VERSION ""

NS_ :

BS_:

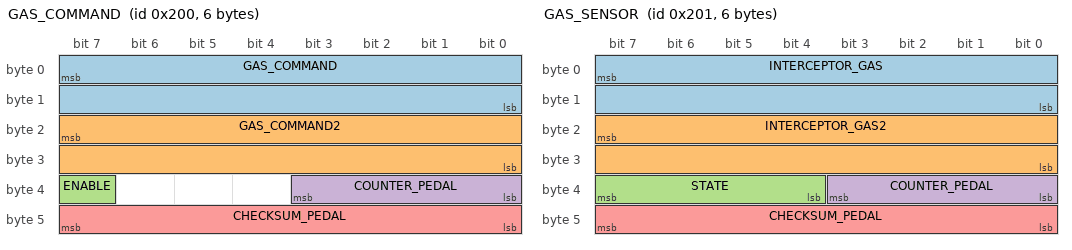
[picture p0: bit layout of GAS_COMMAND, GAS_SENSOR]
BO_ 512 GAS_COMMAND: 6 NEO
 SG_ GAS_COMMAND : 7|16@0+ (0.125677,-75.909) [0|1] "" INTERCEPTOR
 SG_ GAS_COMMAND2 : 23|16@0+ (0.251976,-76.601) [0|1] "" INTERCEPTOR
 SG_ ENABLE : 39|1@0+ (1,0) [0|1] "" INTERCEPTOR
 SG_ COUNTER_PEDAL : 35|4@0+ (1,0) [0|15] "" INTERCEPTOR
 SG_ CHECKSUM_PEDAL : 47|8@0+ (1,0) [0|255] "" INTERCEPTOR

BO_ 513 GAS_SENSOR: 6 INTERCEPTOR
 SG_ INTERCEPTOR_GAS : 7|16@0+ (0.125677,-75.909) [0|1] "" NEO
 SG_ INTERCEPTOR_GAS2 : 23|16@0+ (0.251976,-76.601) [0|1] "" NEO
 SG_ STATE : 39|4@0+ (1,0) [0|15] "" NEO
 SG_ COUNTER_PEDAL : 35|4@0+ (1,0) [0|15] "" NEO
 SG_ CHECKSUM_PEDAL : 47|8@0+ (1,0) [0|255] "" NEO

BO_ 189 EBCMRegenPaddle: 7 K17_EBCM
 SG_ RegenPaddle : 7|4@0+ (1,0) [0|0] ""  NEO

BO_ 190 ECMAcceleratorPos: 6 K20_ECM
 SG_ BrakePedalPos : 15|8@0+ (1,0) [0|0] "sticky"  NEO
 SG_ GasPedalAndAcc : 23|8@0+ (1,0) [0|0] ""  NEO

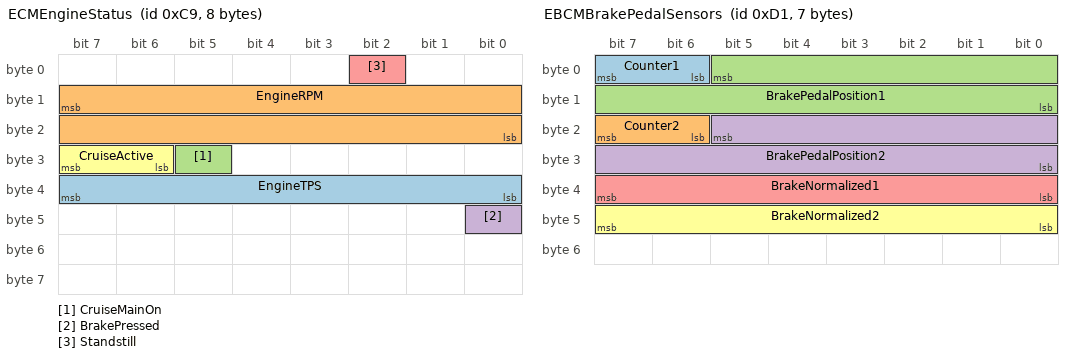
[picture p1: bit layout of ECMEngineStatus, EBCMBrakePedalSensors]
BO_ 201 ECMEngineStatus: 8 K20_ECM
 SG_ EngineTPS : 39|8@0+ (0.392156863,0) [0|100.000000065] "%" NEO
 SG_ EngineRPM : 15|16@0+ (0.25,0) [0|0] "RPM" NEO
 SG_ CruiseMainOn : 29|1@0+ (1,0) [0|1] "" NEO
 SG_ BrakePressed : 40|1@0+ (1,0) [0|1] "" NEO
 SG_ Standstill : 2|1@0+ (1,0) [0|1] "" NEO
 SG_ CruiseActive : 31|2@0+ (1,0) [0|3] "" NEO

BO_ 209 EBCMBrakePedalSensors: 7 K17_EBCM
 SG_ Counter1 : 7|2@0+ (1,0) [0|3] "" XXX
 SG_ Counter2 : 23|2@0+ (1,0) [0|3] "" XXX
 SG_ BrakePedalPosition1 : 5|14@0+ (1,0) [0|16383] "" XXX
 SG_ BrakePedalPosition2 : 21|14@0- (-1,0) [0|16383] "" XXX
 SG_ BrakeNormalized1 : 39|8@0+ (1,0) [0|255] "" XXX
 SG_ BrakeNormalized2 : 47|8@0- (-1,0) [0|255] "" XXX

BO_ 241 EBCMBrakePedalPosition: 6 K17_EBCM
 SG_ BrakePressed : 1|1@0+ (1,0) [0|1] "" XXX
 SG_ BrakePedalPosition : 15|8@0+ (1,0) [0|255] ""  NEO

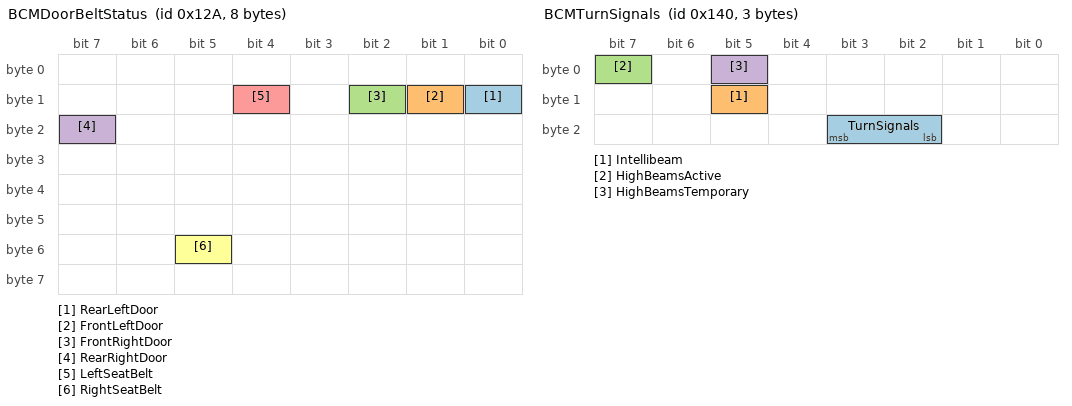
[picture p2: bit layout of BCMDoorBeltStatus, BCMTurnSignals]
BO_ 298 BCMDoorBeltStatus: 8 K9_BCM
 SG_ RearLeftDoor : 8|1@0+ (1,0) [0|0] ""  NEO
 SG_ FrontLeftDoor : 9|1@0+ (1,0) [0|0] ""  NEO
 SG_ FrontRightDoor : 10|1@0+ (1,0) [0|0] ""  NEO
 SG_ RearRightDoor : 23|1@0+ (1,0) [0|0] ""  NEO
 SG_ LeftSeatBelt : 12|1@0+ (1,0) [0|0] ""  NEO
 SG_ RightSeatBelt : 53|1@0+ (1,0) [0|0] ""  NEO

BO_ 309 ECMPRDNL: 8 K20_ECM
 SG_ PRNDL : 2|3@0+ (1,0) [0|0] ""  NEO
 SG_ ESPButton : 4|1@0+ (1,0) [0|1] "" XXX

BO_ 320 BCMTurnSignals: 3 K9_BCM
 SG_ TurnSignals : 19|2@0+ (1,0) [0|0] ""  NEO
 SG_ Intellibeam : 13|1@0+ (1,0) [0|1] "" XXX
 SG_ HighBeamsActive : 7|1@0+ (1,0) [0|1] "" XXX
 SG_ HighBeamsTemporary : 5|1@0+ (1,0) [0|1] "" XXX

BO_ 328 PSCM_148: 1 K43_PSCM

BO_ 381 ESPStatus: 6 K20_ECM
 SG_ TractionControlOn : 5|1@0+ (1,0) [0|0] ""  NEO
 SG_ MSG17D_AccPower : 35|12@0- (1,0) [0|0] ""  NEO

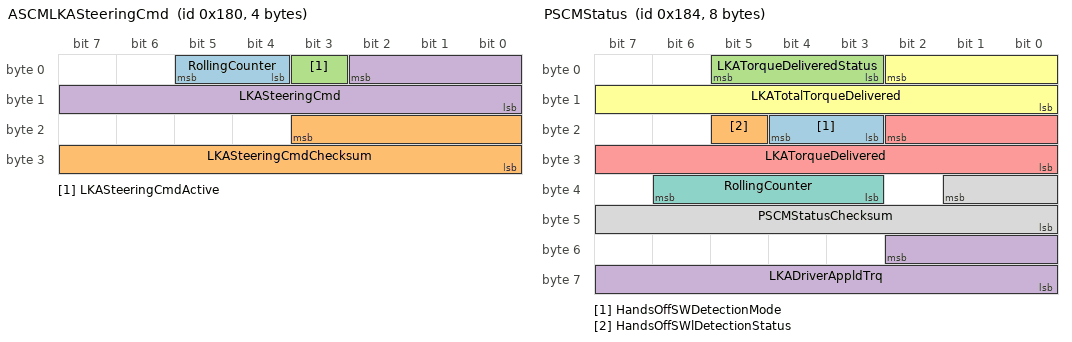
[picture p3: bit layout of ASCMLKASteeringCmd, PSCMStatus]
BO_ 384 ASCMLKASteeringCmd: 4 NEO
 SG_ RollingCounter : 5|2@0+ (1,0) [0|0] ""  NEO
 SG_ LKASteeringCmdChecksum : 19|12@0+ (1,0) [0|0] ""  NEO
 SG_ LKASteeringCmdActive : 3|1@0+ (1,0) [0|0] ""  NEO
 SG_ LKASteeringCmd : 2|11@0- (1,0) [0|0] ""  NEO

BO_ 388 PSCMStatus: 8 K43_PSCM
 SG_ HandsOffSWDetectionMode : 20|2@0+ (1,0) [0|3] "" NEO
 SG_ HandsOffSWlDetectionStatus : 21|1@0+ (1,0) [0|1] "" NEO
 SG_ LKATorqueDeliveredStatus : 5|3@0+ (1,0) [0|7] "" NEO
 SG_ LKADriverAppldTrq : 50|11@0- (0.01,0) [-10.24|10.23] "Nm" NEO
 SG_ LKATorqueDelivered : 18|11@0- (0.01,0) [0|1] "" NEO
 SG_ LKATotalTorqueDelivered : 2|11@0- (0.01,0) [-10.24|10.23] "Nm" NEO
 SG_ RollingCounter : 38|4@0+ (1,0) [0|15] "" XXX
 SG_ PSCMStatusChecksum : 33|10@0+ (1,0) [0|1023] "" XXX

BO_ 417 AcceleratorPedal: 7 XXX
 SG_ AcceleratorPedal : 55|8@0+ (1,0) [0|0] ""  NEO

BO_ 451 GasAndAcc: 8 XXX
 SG_ GasPedalAndAcc2 : 55|8@0+ (1,0) [0|0] ""  NEO

BO_ 452 AcceleratorPedal2: 8 XXX
 SG_ CruiseState : 15|3@0+ (1,0) [0|7] ""  NEO
 SG_ AcceleratorPedal2 : 47|8@0+ (1,0) [0|0] ""  NEO

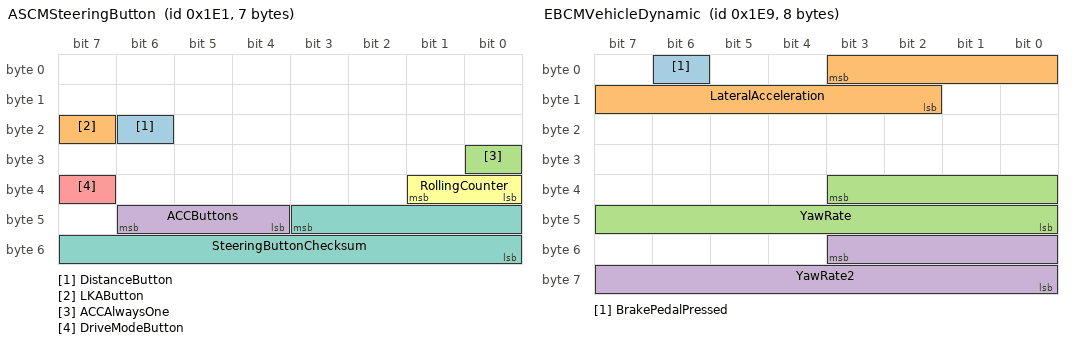
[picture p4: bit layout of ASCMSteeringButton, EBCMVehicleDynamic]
BO_ 481 ASCMSteeringButton: 7 K124_ASCM
 SG_ DistanceButton : 22|1@0+ (1,0) [0|0] ""  NEO
 SG_ LKAButton : 23|1@0+ (1,0) [0|0] ""  NEO
 SG_ ACCAlwaysOne : 24|1@0+ (1,0) [0|1] "" XXX
 SG_ ACCButtons : 46|3@0+ (1,0) [0|0] ""  NEO
 SG_ DriveModeButton : 39|1@0+ (1,0) [0|1] "" XXX
 SG_ RollingCounter : 33|2@0+ (1,0) [0|3] "" NEO
 SG_ SteeringButtonChecksum : 43|12@0+ (1,0) [0|255] "" NEO

BO_ 485 PSCMSteeringAngle: 8 K43_PSCM
 SG_ SteeringWheelAngle : 15|16@0- (0.0625,0) [-2047|2047] "deg"  NEO
 SG_ SteeringWheelRate : 27|12@0- (1,0) [-2047|2047] "deg/s"  NEO

BO_ 489 EBCMVehicleDynamic: 8 K17_EBCM
 SG_ BrakePedalPressed : 6|1@0+ (1,0) [0|0] "" NEO
 SG_ LateralAcceleration : 3|10@0- (0.161,0) [-2047|2047] "m/s2" NEO
 SG_ YawRate : 35|12@0- (0.625,0) [0|1] "" NEO
 SG_ YawRate2 : 51|12@0- (0.0625,0) [-2047|2047] "grad/s" NEO

BO_ 352 BCMImmobilizer: 5 K9_BCM
 SG_ ImmobilizerInfo : 7|32@0+ (1,0) [0|4294967295] "" XXX

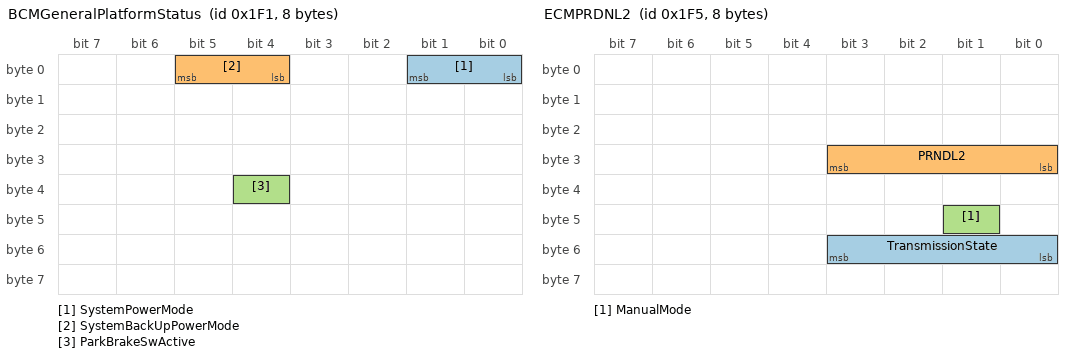
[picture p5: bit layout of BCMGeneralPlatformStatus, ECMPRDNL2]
BO_ 497 BCMGeneralPlatformStatus: 8 K9_BCM
 SG_ SystemPowerMode : 1|2@0+ (1,0) [0|3] "" XXX
 SG_ SystemBackUpPowerMode : 5|2@0+ (1,0) [0|3] "" XXX
 SG_ ParkBrakeSwActive : 36|1@0+ (1,0) [0|3] "" XXX

BO_ 501 ECMPRDNL2: 8 K20_ECM
 SG_ TransmissionState : 48|4@1+ (1,0) [0|7] "" NEO
 SG_ PRNDL2 : 27|4@0+ (1,0) [0|255] "" NEO
 SG_ ManualMode : 41|1@0+ (1,0) [0|1] "" NEO

BO_ 532 BRAKE_RELATED: 6 XXX
 SG_ UserBrakePressure : 0|9@0+ (1,0) [0|511] "" XXX

BO_ 560 EPBStatus: 8 EPB
 SG_ EPBClosed : 12|1@0+ (1,0) [0|1] ""  NEO

BO_ 562 EBCMFrictionBrakeStatus: 8 K17_EBCM
 SG_ FrictionBrakeUnavailable : 46|1@0+ (1,0) [0|1] "" XXX

BO_ 608 SPEED_RELATED: 8 XXX
 SG_ RollingCounter : 5|2@0+ (1,0) [0|0] "" XXX
 SG_ ClusterSpeed : 31|8@0+ (1,0) [0|0] "" XXX

BO_ 711 BECMBatteryVoltageCurrent: 6 K17_EBCM
 SG_ HVBatteryVoltage : 31|12@0+ (0.125,0) [0|511.875] "V"  NEO
 SG_ HVBatteryCurrent : 12|13@0- (0.15,0) [-614.4|614.25] "A"  NEO

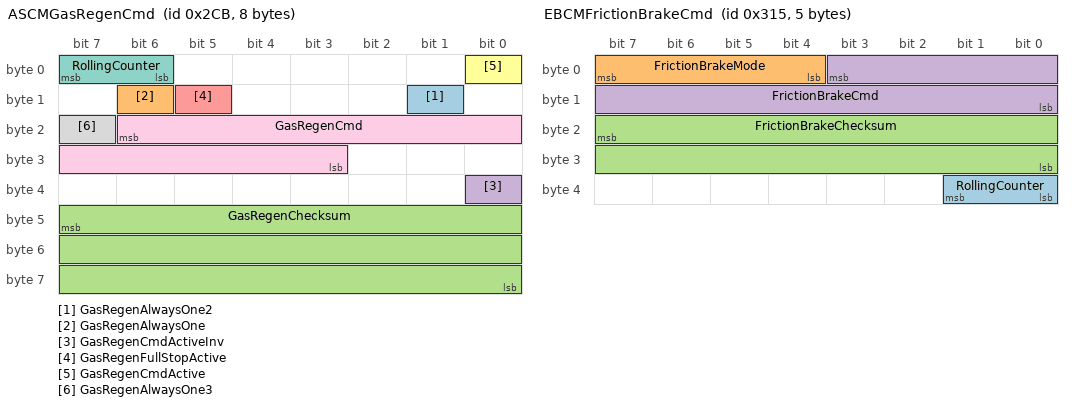
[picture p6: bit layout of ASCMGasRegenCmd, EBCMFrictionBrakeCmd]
BO_ 715 ASCMGasRegenCmd: 8 K124_ASCM
 SG_ GasRegenAlwaysOne2 : 9|1@0+ (1,0) [0|1] ""  NEO
 SG_ GasRegenAlwaysOne : 14|1@0+ (1,0) [0|1] ""  NEO
 SG_ GasRegenChecksum : 47|24@0+ (1,0) [0|0] ""  NEO
 SG_ GasRegenCmdActiveInv : 32|1@0+ (1,0) [0|0] ""  NEO
 SG_ GasRegenFullStopActive : 13|1@0+ (1,0) [0|0] ""  NEO
 SG_ GasRegenCmdActive : 0|1@0+ (1,0) [0|0] ""  NEO
 SG_ RollingCounter : 7|2@0+ (1,0) [0|0] ""  NEO
 SG_ GasRegenAlwaysOne3 : 23|1@0+ (1,0) [0|1] ""  NEO
 SG_ GasRegenCmd : 22|12@0+ (1,0) [0|0] ""  NEO

BO_ 717 ASCM_2CD: 5 K124_ASCM

BO_ 761 BRAKE_RELATED_2: 7 XXX
 SG_ UserBrakePressure2 : 47|9@0+ (1,0) [0|511] "" XXX

BO_ 789 EBCMFrictionBrakeCmd: 5 K124_ASCM
 SG_ RollingCounter : 33|2@0+ (1,0) [0|0] ""  NEO
 SG_ FrictionBrakeMode : 7|4@0+ (1,0) [0|0] ""  NEO
 SG_ FrictionBrakeChecksum : 23|16@0+ (1,0) [0|0] ""  NEO
 SG_ FrictionBrakeCmd : 3|12@0- (1,0) [0|0] ""  NEO

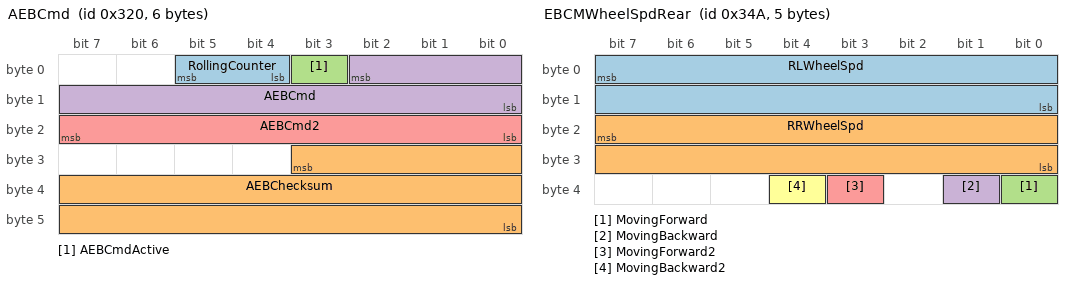
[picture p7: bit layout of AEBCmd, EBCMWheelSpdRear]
BO_ 800 AEBCmd: 6 K124_ASCM
 SG_ RollingCounter : 5|2@0+ (1,0) [0|3] "" NEO
 SG_ AEBChecksum : 27|20@0+ (1,0) [0|0] "" NEO
 SG_ AEBCmdActive : 3|1@1+ (1,0) [0|1] "" NEO
 SG_ AEBCmd : 2|11@0+ (1,0) [0|0] "" NEO
 SG_ AEBCmd2 : 23|8@0+ (1,0) [0|0] "" NEO

BO_ 810 TCICOnStarGPSPosition: 8 K73_TCIC
 SG_ GPSLongitude : 39|32@0+ (1,-2147483648) [0|0] "milliarcsecond"  NEO
 SG_ GPSLatitude : 7|32@0+ (1,0) [0|0] "milliarcsecond"  NEO

BO_ 840 EBCMWheelSpdFront: 5 K17_EBCM
 SG_ FLWheelSpd : 7|16@0+ (0.0311,0) [0|255] "km/h"  NEO
 SG_ FRWheelSpd : 23|16@0+ (0.0311,0) [0|255] "km/h"  NEO

BO_ 842 EBCMWheelSpdRear: 5 K17_EBCM
 SG_ RLWheelSpd : 7|16@0+ (0.0311,0) [0|255] "km/h"  NEO
 SG_ RRWheelSpd : 23|16@0+ (0.0311,0) [0|255] "km/h"  NEO
 SG_ MovingForward : 32|1@0+ (1,0) [0|1] "" XXX
 SG_ MovingBackward : 33|1@0+ (1,0) [0|1] "" XXX
 SG_ MovingForward2 : 35|1@1+ (1,0) [0|1] "" XXX
 SG_ MovingBackward2 : 36|1@0+ (1,0) [0|1] "" XXX

BO_ 869 ASCM_365: 4 K124_ASCM

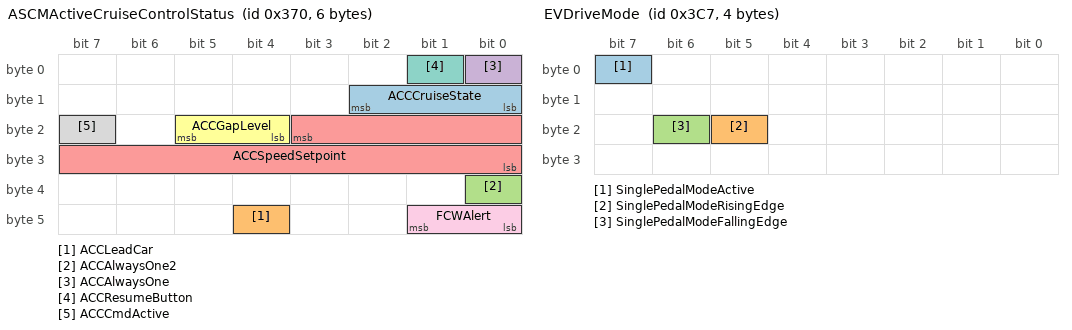
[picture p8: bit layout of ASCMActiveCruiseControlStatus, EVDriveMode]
BO_ 880 ASCMActiveCruiseControlStatus: 6 K124_ASCM
 SG_ ACCCruiseState : 8|3@1+ (1,0) [0|7] "" XXX
 SG_ ACCLeadCar : 44|1@0+ (1,0) [0|0] "" Vector__XXX
 SG_ ACCAlwaysOne2 : 32|1@0+ (1,0) [0|0] "" Vector__XXX
 SG_ ACCAlwaysOne : 0|1@0+ (1,0) [0|0] "" Vector__XXX
 SG_ ACCSpeedSetpoint : 19|12@0+ (0.0625,0) [0|255.9375] "km/h"  NEO
 SG_ ACCGapLevel : 21|2@0+ (1,0) [0|0] ""  NEO
 SG_ ACCResumeButton : 1|1@0+ (1,0) [0|0] ""  NEO
 SG_ ACCCmdActive : 23|1@0+ (1,0) [0|0] ""  NEO
 SG_ FCWAlert : 41|2@0+ (1,0) [0|3] "" XXX

BO_ 967 EVDriveMode: 4 XXX
 SG_ SinglePedalModeActive : 7|1@0+ (1,0) [0|1] "" XXX
 SG_ SinglePedalModeRisingEdge : 21|1@0+ (1,0) [0|1] "" XXX
 SG_ SinglePedalModeFallingEdge : 22|1@0+ (1,0) [0|1] "" XXX

BO_ 977 ECMCruiseControl: 8 K20_ECM
 SG_ CruiseActive : 39|1@0+ (1,0) [0|3] "" NEO
 SG_ CruiseSetSpeed : 19|12@0+ (0.0625,0) [0|0] "km/h" NEO

BO_ 1001 ECMVehicleSpeed: 8 K20_ECM
 SG_ VehicleSpeed : 7|16@0+ (0.01,0) [0|0] "mph"  NEO
 SG_ VehicleSpeedLeft : 39|16@0+ (0.01,0) [0|0] "mph" NEO

BO_ 1033 ASCMKeepAlive: 7 NEO
 SG_ ASCMKeepAliveAllZero : 7|56@0+ (1,0) [0|0] ""  NEO

BO_ 1034 ASCM_40A: 7 K124_ASCM

BO_ 1217 ECMEngineCoolantTemp: 8 K20_ECM
 SG_ EngineCoolantTemp : 23|8@0+ (1,-40) [0|0] "C"  NEO

BO_ 1249 VIN_Part2: 8 K20_ECM
 SG_ VINPart2 : 7|64@0+ (1,0) [0|0] ""  NEO

BO_ 1296 ASCM_510: 4 K124_ASCM

BO_ 1300 VIN_Part1: 8 K20_ECM
 SG_ VINPart1 : 7|64@0+ (1,0) [0|0] ""  NEO

BO_ 1912 PSCM_778: 8 K43_PSCM

BO_ 1930 ASCM_78A: 7 K124_ASCM

BO_TX_BU_ 384 : K124_ASCM,NEO;
BO_TX_BU_ 880 : NEO,K124_ASCM;
BO_TX_BU_ 1033 : K124_ASCM,NEO;
BO_TX_BU_ 715 : NEO,K124_ASCM;
BO_TX_BU_ 789 : NEO,K124_ASCM;
BO_TX_BU_ 800 : NEO,K124_ASCM;

CM_ "AUTOGENERATED FILE, DO NOT EDIT";

CM_ "honda_crv_ex_2017_body.dbc starts here";
VAL_ 159 EPS_HCA_Status 0 "disabled" 1 "initializing" 2 "fault" 3 "ready" 4 "rejected" 5 "active" ;
VAL_ 173 GE_Fahrstufe 5 "P" 6 "R" 7 "N" 8 "D" 9 "S" 10 "E" 13 "T" 14 "T" ;
VAL_ 288 TSK_Status 0 "init" 1 "disabled" 2 "enabled" 3 "regulating" 4 "accel_pedal_override" 5 "brake_only" 6 "temp_fault" 7 "perm_fault" ;
VAL_ 294 EA_ACC_Sollstatus 0 "Init" 1 "ACC_aktivieren" 2 "ACC_deaktivieren" ;
VAL_ 294 EA_Ruckprofil 0 "Init" 1 "Profil_1" 2 "Profil_2" 3 "Profil_3" 4 "Profil_4" 5 "Profil_5" 6 "Profil_6" 7 "Profil_7" ;
VAL_ 294 HCA_01_Sendestatus 0 "HCA_sendet_mit_1000ms" 1 "HCA_sendet_mit_20ms" ;
VAL_ 294 HCA_01_LM_OffSign 0 "positives_Vorzeichen" 1 "negatives_Vorzeichen" ;
VAL_ 294 HCA_01_Status_HCA 0 "deaktiviert" 1 "reserviert" 2 "reserviert" 3 "funktionsbereit" 4 "reserviert" 5 "HCA_Momenteneingriff_1" 6 "MA_Aktiv" 7 "HCA_Momenteneingriff_2" 8 "reserviert" 9 "reserviert" 10 "reserviert" 11 "reserviert" 12 "reserviert" 13 "reserviert" 14 "reserviert" 15 "reserviert" ;
VAL_ 294 EA_Ruckfreigabe 0 "keine_Freigabe" 1 "Freigabe" ;
VAL_ 294 EA_ACC_Wunschgeschwindigkeit 1023 "Init" ;
VAL_ 780 ACC_Wunschgeschw_02 1023 "keine_Anzeige" ;
VAL_ 780 ACC_Status_Prim_Anz 0 "Symbol nicht beleuchtet" 1 "Farbe 1 (typisch 'gruen')" 2 "Farbe 2 (typisch 'rot')" 3 "Farbe 3 (typisch 'gelb')" ;
VAL_ 780 ACC_Abstandsindex 0 "Sonderanzeige_graue_Fahrbahn" 1022 "Sonderanzeige_graue_Fahrbahn" 1023 "Sonderanzeige_Fahrbahn_mit_gruenem_roten_Bereich" ;
VAL_ 780 ACC_Akustik_02 0 "keine_Akustik" 1 "hochpriore_Akustik" 2 "niederpriore_Akustik" 3 "hochpriore_Dauerakustik" ;
VAL_ 780 ACC_Warnung_Verkehrszeichen_1 0 "keine_Warnung_Initialwert" 1 "Warnung" ;
VAL_ 780 ACC_Gesetzte_Zeitluecke 0 "keine_Anzeige" 1 "Zeitluecke_1" 2 "Zeitluecke_2" 3 "Zeitluecke_3" 4 "Zeitluecke_4" 5 "Zeitluecke_5" 6 "nicht_definiert" 7 "nicht_definiert" ;
VAL_ 780 ACC_Optischer_Fahrerhinweis 0 "optischer_Fahrerhinweis_AUS" 1 "optischer_Fahrerhinweis_EIN" ;
VAL_ 780 ACC_Typ_Tachokranz 0 "Tachokranz_lang" 1 "Tachokranz_kurz" ;
VAL_ 780 ACC_Anzeige_Zeitluecke 0 "Anzeige_Zeitluecke_nicht_angefordert" 1 "Anzeige_Zeitluecke_angefordert" ;
VAL_ 780 ACC_Tachokranz 0 "Tachokranz_nicht_beleuchtet" 1 "Tachokranz_beleuchtet" ;
VAL_ 780 ACC_Display_Prio 0 "hoechste_Prio" 1 "mittlere_Prio" 2 "geringe_Prio" 3 "keine_Prio" ;
VAL_ 780 ACC_Relevantes_Objekt 0 "Symbol_nicht_beleuchtet" 1 "Farbe_1_typisch_gruen" 2 "Farbe_2_typisch_rot" 3 "Farbe_3_typisch_gelb" ;
VAL_ 780 ACC_Texte_Primaeranz 0 "keine Anzeige" 1 "ACC nicht verfuegbar !" 2 "Auto_Auto_ _ _" 3 "Auto_ _Auto_ _" 4 "Auto_ _ _Auto_" 5 "Auto_ _ _ _Auto" 6 "Auto_Auto_ _ _ Gong (durchgestrichen)" 7 "Auto_ _Auto_ _ Gong (durchgestrichen)" 8 "Auto_ _ _Auto_ Gong (durchgestrichen)" 9 "Auto_ _ _ _Auto Gong (durchgestrichen)" 10 "ACC bereit" 11 "keine Abstandsregelung" 12 "ACC Sensor Sicht !" 13 "ACC nicht verfuegbar" 14 "o  o  o" 15 "Hochschalten" 16 "ESP Eingriff" 17 "Herunterschalten" 18 "Parkbremse !" 19 "Geschwindigkeitsgrenze" 20 "Waehlhebelposition !" 21 "VDA ACC-Symbol YYY km/h / mph" 22 "Tempolimit XXX km/h / mph" 23 "Kurve XXX km/h / mph" 24 "ACC Abschaltung" 25 "Symbol 'Eieruhr'" 26 "!" 27 "--- km/h / mph" 28 "XXX km/h / mph (Schriftart 2)" 29 "Lenkradwinkel" 30 "Anfahren bestaetigen" 31 "Fahrzeug verloren" 32 "Im Stand nicht moeglich" 33 "Ungueltiger Anfahrbefehl" 34 "Tuer offen !" 35 "Fahrer Gurtschloss offen !" 36 "Schalthebelposition !" 37 "Drehzahl !" 38 "Kurvenassistent aus" 39 "Tempolimit aus" 40 "Abbiegeassistent" 41 "Ortsanfang XXX km/h / mph" 42 "Ortsende XXX km/h / mph" 43 "Tempolimit Ende XXX km/h / mph" 44 "HDC aktiv" 45 "braking guard Bremsruck" 46 "braking guard aus" 47 "braking guard aus" 48 "Uebernehmen !" 49 "Steigung zu gross" 50 "Stehendes Objekt voraus" 51 "SET / 'GRA Symbol'___xxx km/h / mph" 52 "SET / 'GRA Symbol' xxx km/h / mph" 53 "ACC aus" 54 "ACC startet" 55 "ACC reinigen" 56 "ACC Fehler" 57 "ACC haelt an !" 58 "Bremse betaetigen !" 59 "Kupplung betaetigt" 60 "LIM AUS" 61 "LIM AKTIV" 62 "LIM PASSIV" 63 "LIM FEHLER" 64 "Bremse ueberhitzt !" 65 "Bremse haelt !" 66 "ESP PASSIV !" 67 "ACC_anfahrbereit" 68 "Gang_einlegen" 69 "Rechtsueberholen_verhindert" 70 "Linksueberholen_verhindert" 71 "Achtung_Geschwindigkeitsueberschreitung" 72 "Tempolimit_und_Kurvenassistent_nicht_verfuegbar" ;
VAL_ 780 ACC_Wunschgeschw_erreicht 0 "Wunschgeschwindigkeit_nicht_erreicht" 1 "Wunschgeschwindigkeit_erreicht" ;
VAL_ 780 ACC_Typ_Tachokranz_unten 0 "LEDs_an" 1 "LEDs_aus" ;
VAL_ 780 ACC_Status_Anzeige 0 "ACC_GRA_Hauptschalter_aus" 1 "ACC_in_Init_nicht_bei_GRA" 2 "ACC_GRA_passiv" 3 "ACC_GRA_aktiv" 4 "ACC_GRA_im_Hintergrund_uebertreten" 5 "ACC_GRA_Abschaltreaktion" 6 "ACC_reversibel_aus_nicht_bei_GRA" 7 "ACC_GRA_irreversibel_aus" ;
VAL_ 804 ACC_Texte_Sekundaeranz 0 "keine_Anzeige" 1 "Zielfahrzeug_erkannt" 2 "Rechtskurve_voraus" 3 "Linkskurve_voraus" 4 "Tempolimit_voraus" 5 "Sensorsicht" 6 "Anfahrbereit" 7 "Tempolimit_erkannt" 8 "Kreuzung_voraus" 9 "Kreisverkehr_voraus" ;
VAL_ 804 ACC_Texte_Zusatzanz 0 "keine_Anzeige" 1 "ACC_AUS" 2 "ACC_BEREIT" 3 "UEBERTRETEN" 4 "ABSTAND" 5 "DISTANZ_1" 6 "DISTANZ_2" 7 "DISTANZ_3" 8 "DISTANZ_4" 9 "DISTANZ_1__dyn" 10 "DISTANZ_2__dyn" 11 "DISTANZ_3__dyn" 12 "DISTANZ_4__dyn" 13 "DISTANZ_1__stand" 14 "DISTANZ_2__stand" 15 "DISTANZ_3__stand" 16 "DISTANZ_4__stand" 17 "DISTANZ_1__comf" 18 "DISTANZ_2__comf" 19 "DISTANZ_3__comf" 20 "DISTANZ_4__comf" 21 "DISTANZ_1__efficiency" 22 "DISTANZ_2__efficiency" 23 "DISTANZ_3__efficiency" 24 "DISTANZ_4__efficiency" 25 "DISTANZ_5" 26 "DISTANZ_5__dyn" 27 "DISTANZ_5__stand" 28 "DISTANZ_5__comf" 29 "DISTANZ_5__efficiency" 30 "ACHTUNG" 31 "Abstandsanzeige" 32 "Abstandsanz_Warnung_aktiviert" ;
VAL_ 804 ACC_Status_Zusatzanz 0 "keine Anzeige" 1 "Bild 1 (Fzg. Silhouette, typ. farblos)" 2 "Bild 2 (Fzg. Farbe 1, typ. grau)" 3 "Bild 3 (Fzg. Farbe 2, typ. rot)" 4 "Bild 4 (Symbol 1 ACCplus, typ. Doppelfzg. gelb)" 5 "Bild 5 (Symbol 2 ACCplus, typ. Doppelfzg. grau)" 6 "Bild 6 (Fzg. Farbe 2, typ. rot) mit Priorität im Kombi (Pop-up)" ;
VAL_ 804 ACC_Texte 0 "keine_Anzeige" 1 "ACC_nicht_verfuegbar" 2 "ACC_und_AWV_nicht_verfuegbar" 3 "ACC_keine_Sensorsicht" 4 "ACC_und_AWV_keine_Sensorsicht" 5 "ACC_Steigung_zu_gross" 6 "ACC_nur_in_Fahrstufe_verfuegbar" 7 "ACC_Parkbremse_betaetigt" 8 "ACC_ESP_Eingriff" 9 "ACC_Bitte_uebernehmen" 10 "ACC_HDC_betaetigt" 11 "ACC_Geschwindigkeitsgrenze" 12 "ACC_Schalthebelposition" 13 "ACC_Drehzahl" 14 "ACC_Kupplung_betaetigt" 15 "ACC_Aktivierverhinderung" 16 "ACC_Abschaltung" 17 "ACC_Parkassistent_aktiv" 18 "ACC_ESC_aus" 19 "ACC_Charisma_Modus_inkompatibel" 20 "ACC_Stehendes_Objekt_voraus" 21 "ACA_Fahreruebernahme" 22 "ACA_Querfuehrung_nicht_verfuegbar" ;
VAL_ 804 ACC_Texte_braking_guard 0 "keine_Anzeige" 1 "AWV_aus" 2 "AWV_Warnung" 3 "AWV_Demomodus" 4 "AWV_Systemstoerung" 5 "AWV_Eingriff" 6 "AWV_Vorwarnung_aus" 7 "AWV_keine_Sensorsicht" ;
VAL_ 804 ACC_Warnhinweis 0 "kein_Warnhinweis" 1 "Warnhinweis" ;
VAL_ 804 ACC_Zeitluecke_Abstandswarner 61 "Freifahrt" 62 "nicht_definiert" 63 "keine_Anzeige" ;
VAL_ 804 ACC_Abstand_Abstandswarner 509 "Freifahrt" 510 "nicht_definiert" 511 "keine_Anzeige" ;
VAL_ 804 ACC_Tempolimit 0 "keine_Anzeige" 1 "5_zulHoechstgeschw" 2 "7_zulHoechstgeschw" 3 "10_zulHoechstgeschw" 4 "15_zulHoechstgeschw" 5 "20_zulHoechstgeschw" 6 "25_zulHoechstgeschw" 7 "30_zulHoechstgeschw" 8 "35_zulHoechstgeschw" 9 "40_zulHoechstgeschw" 10 "45_zulHoechstgeschw" 11 "50_zulHoechstgeschw" 12 "55_zulHoechstgeschw" 13 "60_zulHoechstgeschw" 14 "65_zulHoechstgeschw" 15 "70_zulHoechstgeschw" 16 "75_zulHoechstgeschw" 17 "80_zulHoechstgeschw" 18 "85_zulHoechstgeschw" 19 "90_zulHoechstgeschw" 20 "95_zulHoechstgeschw" 21 "100_zulHoechstgeschw" 22 "110_zulHoechstgeschw" 23 "120_zulHoechstgeschw" 24 "130_zulHoechstgeschw" 25 "140_zulHoechstgeschw" 26 "150_zulHoechstgeschw" 27 "160_zulHoechstgeschw" 28 "200_zulHoechstgeschw" 30 "250_zulHoechstgeschw" 31 "Ende_zulHoechstgeschw" ;
VAL_ 804 ACC_Charisma_FahrPr 0 "keine_Funktion" 1 "Programm_1" 2 "Programm_2" 3 "Programm_3" 4 "Programm_4" 5 "Programm_5" 6 "Programm_6" 7 "Programm_7" 8 "Programm_8" 9 "Programm_9" 10 "Programm_10" 11 "Programm_11" 12 "Programm_12" 13 "Programm_13" 14 "Programm_14" 15 "Programm_15" ;
VAL_ 804 ACC_Charisma_Status 0 "Init" 1 "verfuegbar" 2 "nicht_verfuegbar" 3 "asynchron_durch_Fahrerwunsch" ;
VAL_ 804 ACC_Texte_Abstandswarner 0 "keine_Anzeige" 1 "Systemstoerung" 2 "keine_Sensorsicht" 3 "zurzeit_eingeschraenkt" ;
VAL_ 290 ACC_limitierte_Anfahrdyn 0 "keine_Limitierung" 1 "Limitierung_Anfahrdynamik_angefordert" ;
VAL_ 290 ACC_nachtr_Stopp_Anf 0 "nicht_angefordert" 1 "angefordert" ;
VAL_ 290 ACC_StartStopp_Info 0 "Motorlauf_langfristig_nicht_notwendig_Stoppfreigabe" 1 "Motoranlauf_nicht_zwingend_notwendig_Stoppverbot_keine_Startanforderung" 2 "Motoranlauf_zwingend_notwendig_Startanforderung" 3 "Systemfehler" ;
VAL_ 290 ACC_Sollbeschleunigung_02 2046 "Neutralwert" 2047 "Fehler" ;
VAL_ 290 ACC_Anfahren 0 "keine_Anforderung_Anfahren" 1 "Anforderung_Anfahren" ;
VAL_ 290 ACC_Anhalten 0 "kein_Anhalten_gewuenscht" 1 "Anhalten_gewuenscht" ;
VAL_ 290 ACC_Typ 0 "Basis_ACC" 1 "ACC_mit_FollowToStop" 2 "ACC_mit_StopAndGo" 3 "ACC_nicht_codiert" ;
VAL_ 290 ACC_Status_ACC 0 "ACC_OFF_Hauptschalter_aus" 1 "ACC_INIT" 2 "ACC_STANDBY" 3 "ACC_AKTIV_regelt" 4 "ACC_OVERRIDE" 5 "ACC_Abschaltreaktion" 6 "reversibler_Fehler_im_ACC_System" 7 "irreversibler_Fehler_im_ACC_System" ;
VAL_ 290 ACC_Minimale_Bremsung 0 "Anforderung_Minimale_Bremsung_nicht_aktiv" 1 "Anforderung_Minimale_Bremsung_aktiv" ;
VAL_ 302 ACC_Anhalteweg 2046 "Neutralwert" 2047 "Fehler" ;
VAL_ 302 ACC_Anhalten 0 "kein_Anhalten_gewuenscht" 1 "Anhalten_gewuenscht" ;
VAL_ 302 ACC_Freilauf_Anf 0 "keine Freilauf-Anforderung" 1 "Freilauf-Anforderung" ;
VAL_ 302 ACC_Freilauf_Info 0 "Freilauf_freigegeben" 1 "kein_Uebergang_in_Freilauf_zulaessig" 2 "Freilauf_nicht_freigegeben" 3 "Freilauf_Anforderung" ;
VAL_ 302 ACC_Anforderung_HMS 0 "keine_Anforderung" 1 "halten" 2 "parken" 3 "halten_Standby" 4 "anfahren" 5 "Loesen_ueber_Rampe" ;
VAL_ 302 ACC_Anfahren 0 "keine_Anforderung_Anfahren" 1 "Anforderung_Anfahren" ;
VAL_ 302 ACC_Folgebeschl 254 "Neutralwert" ;
VAL_ 302 ACC_Sollbeschleunigung_02 2046 "Neutralwert" 2047 "Fehler" ;
VAL_ 279 AWV1_Anf_Prefill 0 "Prefill_nicht_aktivieren" 1 "Prefill_aktivieren" ;
VAL_ 279 ANB_CM_Info 0 "Standard" 1 "Erweitert" ;
VAL_ 279 AWV2_Freigabe 0 "keine_Freigabe" 1 "Freigabe" ;
VAL_ 279 AWV1_HBA_Param 0 "Defaultparametersatz" 1 "Parametersatz_mit_leicht_erhoehter_Empfindlichkeit" 2 "Parametersatz_mit_erhoehter_Empfindlichkeit" 3 "Parametersatz_mit_hoechster_Empfindlichkeit" ;
VAL_ 279 AWV2_Priowarnung 0 "Anzeige_Verlassen_der_Fahrspur_wird_nicht_unterdrueckt" 1 "Anzeige_Verlassen_der_Fahrspur_wird_unterdrueckt" ;
VAL_ 279 ANB_CM_Anforderung 0 "keine_Anforderung" 1 "Anforderung_aktiv" ;
VAL_ 279 ANB_Info_Teilbremsung 0 "Auspraegung_Standard" 1 "Auspraegung_Erweitert" ;
VAL_ 279 ANB_Notfallblinken 0 "kein_ANB_Notfallblinken" 1 "Notfallblinken_ANB_angefordert" ;
VAL_ 279 ANB_Teilbremsung_Freigabe 0 "Teilbremsung_nicht_freigegeben" 1 "Teilbremsung_freigegeben" ;
VAL_ 279 ANB_Zielbremsung_Freigabe 0 "Zielbremsung_nicht_freigegeben" 1 "Zielbremsung_freigegeben" ;
VAL_ 279 AWV_Vorstufe 0 "keine_Notbremsung_erwartet" 1 "Notbremsung_in_Kuerze" ;
VAL_ 279 AWV_Halten 0 "keine_Anforderung" 1 "Anforderung_das_Fzg_im_Stillstand_zu_halten" ;
VAL_ 279 AWV_CityANB_Auspraegung 0 "autom_Bremsung_im_ges_vBereich" 1 "autom_Bremsung_im_def_vBereich" ;
VAL_ 279 PCF_Freigabe 0 "keine_Freigabe_PreCrashFront" 1 "Freigabe_PreCrashFront" ;
VAL_ 279 AWV1_ECD_Anlauf 0 "ECD_Anlauf_nicht_aktivieren" 1 "ECD_Anlauf_aktivieren" ;
VAL_ 279 PCF_Time_to_collision 255 "Objektstatus=0x0__oder_berechneter_TTC_Wert_groesser_als_Maximalwert" ;
VAL_ 679 ACC_Regelgeschw 1023 "keine_Anzeige" ;
VAL_ 679 ACC_Einheit_maxSetzgeschw 0 "kmh" 1 "mph" ;
VAL_ 679 ACC_maxSetzgeschw 511 "Init_Neutralwert" ;
VAL_ 679 ACC_minRegelgeschw 255 "keine_Anzeige" ;
VAL_ 679 ACC_maxRegelgeschw 255 "keine_Anzeige" ;
VAL_ 679 ACC_Tempolimitassistent 0 "keine_Anzeige" 1 "Tempolimitassistent_aktiv" 2 "Tempolimitassistent_nicht_verfuegbar" 3 "Tempolimitassistent_Fahreruebernahme" ;
VAL_ 679 ACC_Kurvenassistent 0 "keine_Anzeige" 1 "Kreuzung" 2 "Rechtskurve" 3 "Linkskurve" 4 "Kreisverkehr" ;
VAL_ 679 ACC_RUV 0 "keine_Anzeige" 1 "RUV_aktiv_Rechtsverkehr" 2 "RUV_aktiv_Linksverkehr" ;
VAL_ 679 ACC_Tachokranz 0 "Tachokranz_nicht_beleuchtet" 1 "Tachokranz_beleuchtet" ;
VAL_ 679 ACC_Typ_Tachokranz_unten 0 "LEDs_an" 1 "LEDs_aus" ;
VAL_ 679 ACC_ENG_Texte 0 "keine_Anzeige" 1 "keine_Laenderverfuegbarkeit" 2 "nicht_verfuegbar" 3 "Geschwindigkeitsgrenze" ;
VAL_ 681 AWV_Warnung 0 "keine_Anzeige" 1 "latente_Vorwarnung" 2 "Vorwarnung" 3 "Akutwarnung" 4 "Eingriff" 5 "Fahreruebernahmeaufforderung" 6 "Abbiegewarnung" ;
VAL_ 681 AWV_Texte 0 "keine_Anzeige" 1 "Systemstoerung" 2 "keine_Sensorsicht" 3 "Demomodus" 4 "System_aus" 5 "nicht_definiert" 6 "ESC_aus" 7 "zurzeit_eingeschraenkt" ;
VAL_ 681 AWV_Status_Anzeige 0 "Init" 1 "verfuegbar" 2 "nicht_verfuegbar" ;
VAL_ 681 AWV_Einstellung_System_FSG 0 "deaktiviert" 1 "aktiviert" ;
VAL_ 681 AWV_Einstellung_Warnung_FSG 0 "Aus" 1 "Setting_2" 2 "Setting_3" 3 "Setting_4" 4 "Setting_5" 5 "Ein" ;
VAL_ 681 AWV_Warnlevel 0 "keine_Gefaehrdung" 63 "max_Gefaehrdung" ;
VAL_ 391 GearPosition 2 "P" 3 "R" 4 "N" 5 "D" 6 "D" ;
VAL_ 391 RegenBrakingMode 0 "default" 1 "B1" 2 "B2" 3 "B3" ;
VAL_ 870 Fast_Send_Rate_Active 0 "1 Hz" 1 "50 Hz" ;
VAL_ 1720 KBI_Variante_USA 0 "keine USA-Variante" 1 "USA-Variante" ;
VAL_ 1720 KBI_Variante 0 "Zeiger Kombiinstrument" 1 "Volldisplay Kombiinstrument" ;
VAL_ 1720 KBI_BCmE_aktiv 0 "Anzeige_nicht_aktiv" 1 "Anzeige_aktiv" ;
VAL_ 1720 KBI_Sparhinweis_quittiert 0 "nicht_quittiert" 1 "quittiert" ;
VAL_ 1720 KBI_Tankfuellstand_Prozent 126 "Init" 127 "Fehler" ;
VAL_ 1720 KBI_Nachtanken_erkannt 0 "Geberbetrieb" 1 "Nachtankmodus" ;
VAL_ 1720 KBI_Tankinhalt_hochaufl 16382 "Init" 16383 "Fehler" ;
